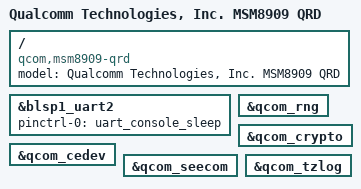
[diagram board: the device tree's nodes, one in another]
/* Copyright (c) 2014, The Linux Foundation. All rights reserved.
 *
 * This program is free software; you can redistribute it and/or modify
 * it under the terms of the GNU General Public License version 2 and
 * only version 2 as published by the Free Software Foundation.
 *
 * This program is distributed in the hope that it will be useful,
 * but WITHOUT ANY WARRANTY; without even the implied warranty of
 * MERCHANTABILITY or FITNESS FOR A PARTICULAR PURPOSE.  See the
 * GNU General Public License for more details.
 */

#include "msm8909.dtsi"
#include "msm8909-pinctrl.dtsi"

/ {
	model = "Qualcomm Technologies, Inc. MSM8909 QRD";
	compatible = "qcom,msm8909-qrd", "qcom,msm8909", "qcom,qrd";
};

&blsp1_uart2 {
	status = "ok";
	pinctrl-names = "default";
	pinctrl-0 = <&uart_console_sleep>;
};

&qcom_rng {
	status = "okay";
};

&qcom_crypto {
	status = "okay";
};

&qcom_cedev {
	status = "okay";
};

&qcom_seecom {
	status = "okay";
};

&qcom_tzlog {
	status = "okay";
};
